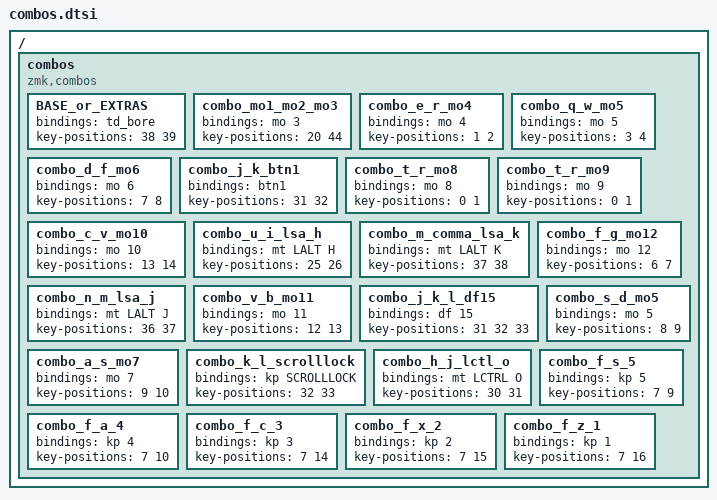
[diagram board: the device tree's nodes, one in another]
/ {
    combos {
        compatible = "zmk,combos";

        BASE_or_EXTRAS {
            bindings = <&td_bore>;
            key-positions = <38 39>;
        };

        combo_mo1_mo2_mo3 {
            bindings = <&mo 3>;
            key-positions = <20 44>;
        };
        combo_e_r_mo4 {
            bindings = <&mo 4>;
            key-positions = <1 2>;
        };
        combo_q_w_mo5 {
            bindings = <&mo 5>;
            key-positions = <3 4>;
        };
        combo_d_f_mo6 {
            bindings = <&mo 6>;
            key-positions = <7 8>;
        };
        combo_j_k_btn1 {
            bindings = <&btn1>;
            key-positions = <31 32>;
        };
        combo_t_r_mo8 {
            bindings = <&mo 8>;
            key-positions = <0 1>;
        };
        combo_t_r_mo9 {
            bindings = <&mo 9>;
            key-positions = <0 1>;
        };
        combo_c_v_mo10 {
            bindings = <&mo 10>;
            key-positions = <13 14>;
        };
        combo_u_i_lsa_h {
            bindings = <&mt LALT H>;
            key-positions = <25 26>;
        };
        combo_m_comma_lsa_k {
            bindings = <&mt LALT K>;
            key-positions = <37 38>;
        };
        combo_n_m_lsa_j {
            bindings = <&mt LALT J>;
            key-positions = <36 37>;
        };
        combo_v_b_mo11 {
            bindings = <&mo 11>;
            key-positions = <12 13>;
        };
        combo_f_g_mo12 {
            bindings = <&mo 12>;
            key-positions = <6 7>;
        };
        combo_j_k_l_df15 {
            bindings = <&df 15>;
            key-positions = <31 32 33>;
        };
        combo_s_d_mo5 {
            bindings = <&mo 5>;
            key-positions = <8 9>;
        };
        combo_a_s_mo7 {
            bindings = <&mo 7>;
            key-positions = <9 10>;
        };
        combo_k_l_scrolllock {
            bindings = <&kp SCROLLLOCK>;
            key-positions = <32 33>;
        };
        combo_h_j_lctl_o {
            bindings = <&mt LCTRL O>;
            key-positions = <30 31>;
        };
        combo_f_s_5 {
            bindings = <&kp 5>;
            key-positions = <7 9>;
        };
        combo_f_a_4 {
            bindings = <&kp 4>;
            key-positions = <7 10>;
        };
        combo_f_c_3 {
            bindings = <&kp 3>;
            key-positions = <7 14>;
        };
        combo_f_x_2 {
            bindings = <&kp 2>;
            key-positions = <7 15>;
        };
        combo_f_z_1 {
            bindings = <&kp 1>;
            key-positions = <7 16>;
        };
    };
};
